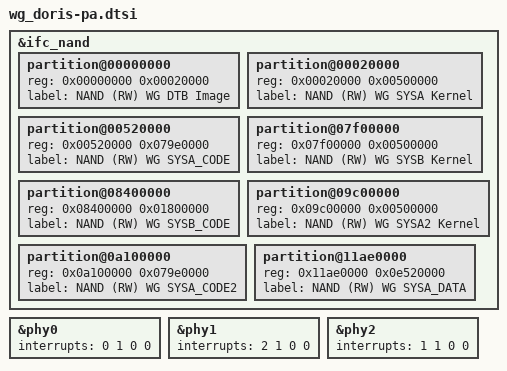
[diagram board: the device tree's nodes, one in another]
/*
 * P1010 RDB-pb Device Tree Source stub (no addresses or top-level ranges)
 *
 * Copyright 2013 Freescale Semiconductor Inc.
 *
 * Redistribution and use in source and binary forms, with or without
 * modification, are permitted provided that the following conditions are met:
 *     * Redistributions of source code must retain the above copyright
 *       notice, this list of conditions and the following disclaimer.
 *     * Redistributions in binary form must reproduce the above copyright
 *       notice, this list of conditions and the following disclaimer in the
 *       documentation and/or other materials provided with the distribution.
 *     * Neither the name of Freescale Semiconductor nor the
 *       names of its contributors may be used to endorse or promote products
 *       derived from this software without specific prior written permission.
 *
 *
 * ALTERNATIVELY, this software may be distributed under the terms of the
 * GNU General Public License ("GPL") as published by the Free Software
 * Foundation, either version 2 of that License or (at your option) any
 * later version.
 *
 * THIS SOFTWARE IS PROVIDED BY Freescale Semiconductor ``AS IS'' AND ANY
 * EXPRESS OR IMPLIED WARRANTIES, INCLUDING, BUT NOT LIMITED TO, THE IMPLIED
 * WARRANTIES OF MERCHANTABILITY AND FITNESS FOR A PARTICULAR PURPOSE ARE
 * DISCLAIMED. IN NO EVENT SHALL Freescale Semiconductor BE LIABLE FOR ANY
 * DIRECT, INDIRECT, INCIDENTAL, SPECIAL, EXEMPLARY, OR CONSEQUENTIAL DAMAGES
 * (INCLUDING, BUT NOT LIMITED TO, PROCUREMENT OF SUBSTITUTE GOODS OR SERVICES;
 * LOSS OF USE, DATA, OR PROFITS; OR BUSINESS INTERRUPTION) HOWEVER CAUSED AND
 * ON ANY THEORY OF LIABILITY, WHETHER IN CONTRACT, STRICT LIABILITY, OR TORT
 * (INCLUDING NEGLIGENCE OR OTHERWISE) ARISING IN ANY WAY OUT OF THE USE OF THIS
 * SOFTWARE, EVEN IF ADVISED OF THE POSSIBILITY OF SUCH DAMAGE.
 */

&ifc_nand {
	partition@00000000 {
		/* ACTUAL: NAND 128KB for DTB Image partiton */
		reg = <0x00000000 0x00020000>;
		label = "NAND (RW) WG DTB Image";
	};

	/* rest of the NAND partitions */
	partition@00020000 {
		/* 5MB for sysa kernel */
		reg = <0x00020000 0x00500000>;
		label = "NAND (RW) WG SYSA Kernel";
	};

	partition@00520000 {
		/* 121MB for sysa code */
		reg = <0x00520000 0x079e0000>;
		label = "NAND (RW) WG SYSA_CODE";
	};

	partition@07f00000 {
		/* 5MB for sysb kernel */
		reg = <0x07f00000 0x00500000>;
		label = "NAND (RW) WG SYSB Kernel";
	};

	partition@08400000 {
		/* 24MB for sysb code */
		reg = <0x08400000 0x01800000>;
		label = "NAND (RW) WG SYSB_CODE";
	};

	partition@09c00000 {
		/* 5MB for sysa2 kernel */
		reg = <0x09c00000 0x00500000>;
		label = "NAND (RW) WG SYSA2 Kernel";
	};

	partition@0a100000 {
		/* 121MB for sysa2 code */
		reg = <0x0a100000 0x079e0000>;
		label = "NAND (RW) WG SYSA_CODE2";
	};

	partition@11ae0000 {
		/* 229MB for sysa data */
		reg = <0x11ae0000 0x0e520000>;
		label = "NAND (RW) WG SYSA_DATA";
	};
};

&phy0 {
	interrupts = <0 1 0 0>;
};

&phy1 {
	interrupts = <2 1 0 0>;
};

&phy2 {
	interrupts = <1 1 0 0>;
};
